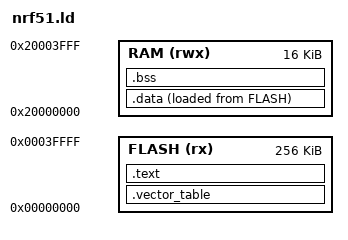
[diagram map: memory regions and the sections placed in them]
/* Linker script for nRF51822 (BBC micro:bit v1).
 *   256 KB flash @ 0x00000000
 *    16 KB SRAM  @ 0x20000000
 */
ENTRY(Reset_Handler)

MEMORY
{
    FLASH (rx)  : ORIGIN = 0x00000000, LENGTH = 256K
    RAM   (rwx) : ORIGIN = 0x20000000, LENGTH = 16K
}

SECTIONS
{
    .vector_table : {
        KEEP(*(.vector_table))
    } > FLASH

    .text : {
        *(.text*)
        *(.rodata*)
        . = ALIGN(4);
    } > FLASH

    _sidata = LOADADDR(.data);
    .data : {
        . = ALIGN(4);
        _sdata = .;
        *(.data*)
        . = ALIGN(4);
        _edata = .;
    } > RAM AT > FLASH

    .bss : {
        . = ALIGN(4);
        _sbss = .;
        *(.bss*)
        *(COMMON)
        . = ALIGN(4);
        _ebss = .;
    } > RAM

    _stack_top = ORIGIN(RAM) + LENGTH(RAM);

    /DISCARD/ : { *(.ARM.exidx*) *(.ARM.extab*) }
}
